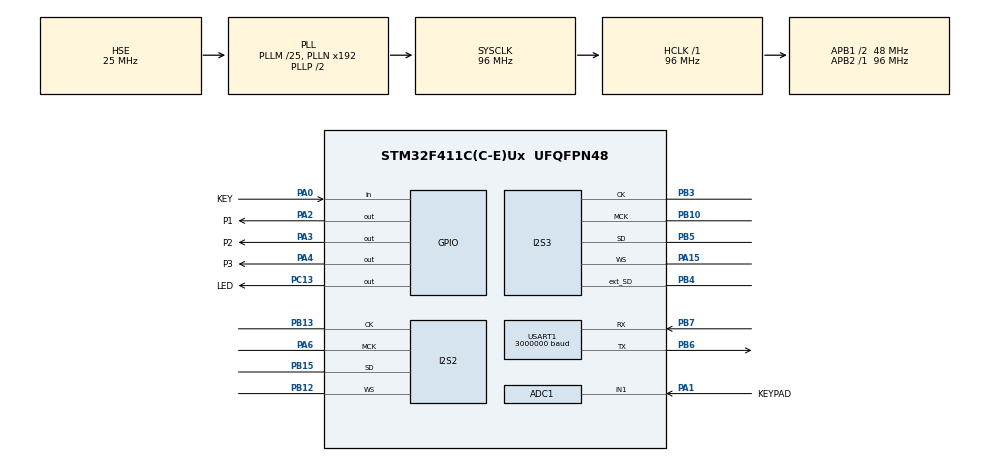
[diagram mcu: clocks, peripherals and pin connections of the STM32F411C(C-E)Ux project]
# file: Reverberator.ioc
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ADC1.Channel-0\#ChannelRegularConversion=ADC_CHANNEL_1
ADC1.ClockPrescaler=ADC_CLOCK_SYNC_PCLK_DIV8
ADC1.NbrOfConversionFlag=1
ADC1.Rank-0\#ChannelRegularConversion=1
ADC1.SamplingTime-0\#ChannelRegularConversion=ADC_SAMPLETIME_84CYCLES
ADC1.master=1
Dma.Request0=SPI3_RX
Dma.Request1=USART1_TX
Dma.Request2=SPI2_TX
Dma.SPI2_TX.2.Direction=DMA_MEMORY_TO_PERIPH
Dma.SPI2_TX.2.FIFOMode=DMA_FIFOMODE_DISABLE
Dma.SPI2_TX.2.Instance=DMA1_Stream4
Dma.SPI2_TX.2.MemDataAlignment=DMA_MDATAALIGN_HALFWORD
Dma.SPI2_TX.2.MemInc=DMA_MINC_ENABLE
Dma.SPI2_TX.2.Mode=DMA_CIRCULAR
Dma.SPI2_TX.2.PeriphDataAlignment=DMA_PDATAALIGN_HALFWORD
Dma.SPI2_TX.2.PeriphInc=DMA_PINC_DISABLE
Dma.SPI2_TX.2.Priority=DMA_PRIORITY_LOW
Dma.SPI3_RX.0.Direction=DMA_PERIPH_TO_MEMORY
Dma.SPI3_RX.0.FIFOMode=DMA_FIFOMODE_DISABLE
Dma.SPI3_RX.0.Instance=DMA1_Stream0
Dma.SPI3_RX.0.MemDataAlignment=DMA_MDATAALIGN_HALFWORD
Dma.SPI3_RX.0.MemInc=DMA_MINC_ENABLE
Dma.SPI3_RX.0.Mode=DMA_CIRCULAR
Dma.SPI3_RX.0.PeriphDataAlignment=DMA_PDATAALIGN_HALFWORD
Dma.SPI3_RX.0.PeriphInc=DMA_PINC_DISABLE
Dma.SPI3_RX.0.Priority=DMA_PRIORITY_LOW
Dma.USART1_TX.1.Direction=DMA_MEMORY_TO_PERIPH
Dma.USART1_TX.1.FIFOMode=DMA_FIFOMODE_DISABLE
Dma.USART1_TX.1.Instance=DMA2_Stream7
Dma.USART1_TX.1.MemDataAlignment=DMA_MDATAALIGN_BYTE
Dma.USART1_TX.1.MemInc=DMA_MINC_ENABLE
Dma.USART1_TX.1.Mode=DMA_NORMAL
Dma.USART1_TX.1.PeriphDataAlignment=DMA_PDATAALIGN_BYTE
Dma.USART1_TX.1.PeriphInc=DMA_PINC_DISABLE
Dma.USART1_TX.1.Priority=DMA_PRIORITY_LOW
FREERTOS.Queues01=keysQueue,16,uint8_t,0,Static,keysQueueBuffer,keysQueueControlBlock
FREERTOS.Tasks01=defaultTask,0,256,runDefaultTask,Default,NULL,Dynamic,NULL,NULL;keyboardTask,0,256,runKeyboardTask,Default,NULL,Dynamic,NULL,NULL
FREERTOS.configENABLE_FPU=1
FREERTOS.configUSE_NEWLIB_REENTRANT=1
I2S2.AudioFreq=I2S_AUDIOFREQ_48K
I2S2.DataFormat=I2S_DATAFORMAT_16B_EXTENDED
I2S2.ErrorAudioFreq=1.72 %
I2S2.FullDuplexMode=I2S_FULLDUPLEXMODE_DISABLE
I2S2.Instance=SPI$Index
I2S2.RealAudioFreq=48.828 KHz
I2S2.Standard=I2S_STANDARD_MSB
I2S2.VirtualMode=I2S_MODE_MASTER
I2S3.AudioFreq=I2S_AUDIOFREQ_48K
I2S3.DataFormat=I2S_DATAFORMAT_16B_EXTENDED
I2S3.ErrorAudioFreq=1.72 %
I2S3.FullDuplexMode=I2S_FULLDUPLEXMODE_ENABLE
I2S3.Instance=SPI$Index
I2S3.Mode=I2S_MODE_MASTER_RX
I2S3.RealAudioFreq=48.828 KHz
I2S3.Standard=I2S_STANDARD_PHILIPS
I2S3.VirtualMode=I2S_MODE_MASTER
Mcu.Family=STM32F4
Mcu.Name=STM32F411C(C-E)Ux
Mcu.Package=UFQFPN48
NVIC.DMA1_Stream0_IRQn=true\:5\:0\:false\:false\:true\:true\:false\:true
NVIC.DMA1_Stream4_IRQn=true\:5\:0\:false\:false\:true\:true\:false\:true
NVIC.DMA2_Stream7_IRQn=true\:5\:0\:false\:false\:true\:true\:false\:true
NVIC.PriorityGroup=NVIC_PRIORITYGROUP_4
NVIC.TIM1_UP_TIM10_IRQn=true\:15\:0\:false\:false\:true\:false\:false\:true
NVIC.TimeBase=TIM1_UP_TIM10_IRQn
NVIC.TimeBaseIP=TIM10
PA0-WKUP.GPIO_Label=KEY
PA0-WKUP.GPIO_PuPd=GPIO_PULLUP
PA0-WKUP.Signal=GPIO_Input
PA1.GPIO_Label=KEYPAD
PA1.Signal=ADCx_IN1
PA13.Mode=Serial_Wire
PA13.Signal=SYS_JTMS-SWDIO
PA14.Mode=Serial_Wire
PA14.Signal=SYS_JTCK-SWCLK
PA15.Mode=Full_Duplex_Master
PA15.Signal=I2S3_WS
PA2.GPIO_Label=P1
PA2.Signal=GPIO_Output
PA3.GPIO_Label=P2
PA3.Signal=GPIO_Output
PA4.GPIO_Label=P3
PA4.Signal=GPIO_Output
PA6.Mode=Master_Clock_Activated
PA6.Signal=I2S2_MCK
PB10.Mode=Master_Clock_Activated
PB10.Signal=I2S3_MCK
PB12.Mode=Half_Duplex_Master
PB12.Signal=I2S2_WS
PB13.Mode=Half_Duplex_Master
PB13.Signal=I2S2_CK
PB15.Mode=Half_Duplex_Master
PB15.Signal=I2S2_SD
PB3.Mode=Full_Duplex_Master
PB3.Signal=I2S3_CK
PB4.Mode=Full_Duplex_Master
PB4.Signal=I2S3_ext_SD
PB5.Mode=Full_Duplex_Master
PB5.Signal=I2S3_SD
PB6.Mode=Asynchronous
PB6.Signal=USART1_TX
PB7.Mode=Asynchronous
PB7.Signal=USART1_RX
PC13-ANTI_TAMP.GPIO_Label=LED
PC13-ANTI_TAMP.Signal=GPIO_Output
PC14-OSC32_IN.Mode=LSE-External-Oscillator
PC14-OSC32_IN.Signal=RCC_OSC32_IN
PC15-OSC32_OUT.Mode=LSE-External-Oscillator
PC15-OSC32_OUT.Signal=RCC_OSC32_OUT
PH0\ -\ OSC_IN.Mode=HSE-External-Oscillator
PH0\ -\ OSC_IN.Signal=RCC_OSC_IN
PH1\ -\ OSC_OUT.Mode=HSE-External-Oscillator
PH1\ -\ OSC_OUT.Signal=RCC_OSC_OUT
ProjectManager.HeapSize=0x8000
ProjectManager.StackSize=0x400
ProjectManager.TargetToolchain=STM32CubeIDE
RCC.48MHZClocksFreq_Value=48000000
RCC.AHBFreq_Value=96000000
RCC.APB1CLKDivider=RCC_HCLK_DIV2
RCC.APB1Freq_Value=48000000
RCC.APB1TimFreq_Value=96000000
RCC.APB2Freq_Value=96000000
RCC.APB2TimFreq_Value=96000000
RCC.CortexFreq_Value=96000000
RCC.HCLKFreq_Value=96000000
RCC.HSE_VALUE=25000000
RCC.HSI_VALUE=16000000
RCC.PLLM=25
RCC.PLLSourceVirtual=RCC_PLLSOURCE_HSE
RCC.SYSCLKFreq_VALUE=96000000
RCC.SYSCLKSource=RCC_SYSCLKSOURCE_PLLCLK
RCC.VCOOutputFreq_Value=192000000
SH.ADCx_IN1.0=ADC1_IN1,IN1
USART1.BaudRate=3000000
USART1.VirtualMode=VM_ASYNC
VP_FREERTOS_VS_CMSIS_V1.Mode=CMSIS_V1
VP_SYS_VS_tim10.Mode=TIM10
board=custom

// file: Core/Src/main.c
/* USER CODE BEGIN Header */
/**
  ******************************************************************************
  * @file           : main.c
  * @brief          : Main program body
  ******************************************************************************
  * @attention
  *
  * Copyright (c) 2022 STMicroelectronics.
  * All rights reserved.
  *
  * This software is licensed under terms that can be found in the LICENSE file
  * in the root directory of this software component.
  * If no LICENSE file comes with this software, it is provided AS-IS.
  *
  ******************************************************************************
  */
/* USER CODE END Header */
#include "main.h"
#include "cmsis_os.h"

/* USER CODE BEGIN Includes */
#include "processing.h"
#include "interface.h"

/* USER CODE END Includes */

ADC_HandleTypeDef hadc1;

I2S_HandleTypeDef hi2s2;
I2S_HandleTypeDef hi2s3;
DMA_HandleTypeDef hdma_spi2_tx;
DMA_HandleTypeDef hdma_spi3_rx;

UART_HandleTypeDef huart1;
DMA_HandleTypeDef hdma_usart1_tx;

osThreadId defaultTaskHandle;
osThreadId keyboardTaskHandle;
osMessageQId keysQueueHandle;
uint8_t keysQueueBuffer[ 16 * sizeof( uint8_t ) ];
osStaticMessageQDef_t keysQueueControlBlock;

void SystemClock_Config(void);
void PeriphCommonClock_Config(void);
static void MX_GPIO_Init(void);
static void MX_DMA_Init(void);
static void MX_I2S3_Init(void);
static void MX_USART1_UART_Init(void);
static void MX_I2S2_Init(void);
static void MX_ADC1_Init(void);
void runDefaultTask(void const * argument);
void runKeyboardTask(void const * argument);

int main(void)
{

  /* MCU Configuration--------------------------------------------------------*/

  /* Reset of all peripherals, Initializes the Flash interface and the Systick. */
  HAL_Init();

  /* Configure the system clock */
  SystemClock_Config();

/* Configure the peripherals common clocks */
  PeriphCommonClock_Config();

  /* Initialize all configured peripherals */
  MX_GPIO_Init();
  MX_DMA_Init();
  MX_I2S3_Init();
  MX_USART1_UART_Init();
  MX_I2S2_Init();
  MX_ADC1_Init();

  /* Create the queue(s) */
  /* definition and creation of keysQueue */
  osMessageQStaticDef(keysQueue, 16, uint8_t, keysQueueBuffer, &keysQueueControlBlock);
  keysQueueHandle = osMessageCreate(osMessageQ(keysQueue), NULL);

  /* Create the thread(s) */
  /* definition and creation of defaultTask */
  osThreadDef(defaultTask, runDefaultTask, osPriorityNormal, 0, 256);
  defaultTaskHandle = osThreadCreate(osThread(defaultTask), NULL);

  /* definition and creation of keyboardTask */
  osThreadDef(keyboardTask, runKeyboardTask, osPriorityNormal, 0, 256);
  keyboardTaskHandle = osThreadCreate(osThread(keyboardTask), NULL);

  /* Start scheduler */
  osKernelStart();

  /* We should never get here as control is now taken by the scheduler */
  /* Infinite loop */
  while (1)
  {

  }
}

void SystemClock_Config(void)
{
  RCC_OscInitTypeDef RCC_OscInitStruct = {0};
  RCC_ClkInitTypeDef RCC_ClkInitStruct = {0};

  /** Configure the main internal regulator output voltage
  */
  __HAL_RCC_PWR_CLK_ENABLE();
  __HAL_PWR_VOLTAGESCALING_CONFIG(PWR_REGULATOR_VOLTAGE_SCALE1);
  /** Initializes the RCC Oscillators according to the specified parameters
  * in the RCC_OscInitTypeDef structure.
  */
  RCC_OscInitStruct.OscillatorType = RCC_OSCILLATORTYPE_HSE;
  RCC_OscInitStruct.HSEState = RCC_HSE_ON;
  RCC_OscInitStruct.PLL.PLLState = RCC_PLL_ON;
  RCC_OscInitStruct.PLL.PLLSource = RCC_PLLSOURCE_HSE;
  RCC_OscInitStruct.PLL.PLLM = 25;
  RCC_OscInitStruct.PLL.PLLN = 192;
  RCC_OscInitStruct.PLL.PLLP = RCC_PLLP_DIV2;
  RCC_OscInitStruct.PLL.PLLQ = 4;
  if (HAL_RCC_OscConfig(&RCC_OscInitStruct) != HAL_OK)
  {
    Error_Handler();
  }
  /** Initializes the CPU, AHB and APB buses clocks
  */
  RCC_ClkInitStruct.ClockType = RCC_CLOCKTYPE_HCLK|RCC_CLOCKTYPE_SYSCLK
                              |RCC_CLOCKTYPE_PCLK1|RCC_CLOCKTYPE_PCLK2;
  RCC_ClkInitStruct.SYSCLKSource = RCC_SYSCLKSOURCE_PLLCLK;
  RCC_ClkInitStruct.AHBCLKDivider = RCC_SYSCLK_DIV1;
  RCC_ClkInitStruct.APB1CLKDivider = RCC_HCLK_DIV2;
  RCC_ClkInitStruct.APB2CLKDivider = RCC_HCLK_DIV1;

  if (HAL_RCC_ClockConfig(&RCC_ClkInitStruct, FLASH_LATENCY_3) != HAL_OK)
  {
    Error_Handler();
  }
}

void PeriphCommonClock_Config(void)
{
  RCC_PeriphCLKInitTypeDef PeriphClkInitStruct = {0};

  /** Initializes the peripherals clock
  */
  PeriphClkInitStruct.PeriphClockSelection = RCC_PERIPHCLK_I2S;
  PeriphClkInitStruct.PLLI2S.PLLI2SN = 192;
  PeriphClkInitStruct.PLLI2S.PLLI2SM = 16;
  PeriphClkInitStruct.PLLI2S.PLLI2SR = 2;
  if (HAL_RCCEx_PeriphCLKConfig(&PeriphClkInitStruct) != HAL_OK)
  {
    Error_Handler();
  }
}

static void MX_ADC1_Init(void)
{

  ADC_ChannelConfTypeDef sConfig = {0};

  /** Configure the global features of the ADC (Clock, Resolution, Data Alignment and number of conversion)
  */
  hadc1.Instance = ADC1;
  hadc1.Init.ClockPrescaler = ADC_CLOCK_SYNC_PCLK_DIV8;
  hadc1.Init.Resolution = ADC_RESOLUTION_12B;
  hadc1.Init.ScanConvMode = DISABLE;
  hadc1.Init.ContinuousConvMode = DISABLE;
  hadc1.Init.DiscontinuousConvMode = DISABLE;
  hadc1.Init.ExternalTrigConvEdge = ADC_EXTERNALTRIGCONVEDGE_NONE;
  hadc1.Init.ExternalTrigConv = ADC_SOFTWARE_START;
  hadc1.Init.DataAlign = ADC_DATAALIGN_RIGHT;
  hadc1.Init.NbrOfConversion = 1;
  hadc1.Init.DMAContinuousRequests = DISABLE;
  hadc1.Init.EOCSelection = ADC_EOC_SINGLE_CONV;
  if (HAL_ADC_Init(&hadc1) != HAL_OK)
  {
    Error_Handler();
  }
  /** Configure for the selected ADC regular channel its corresponding rank in the sequencer and its sample time.
  */
  sConfig.Channel = ADC_CHANNEL_1;
  sConfig.Rank = 1;
  sConfig.SamplingTime = ADC_SAMPLETIME_84CYCLES;
  if (HAL_ADC_ConfigChannel(&hadc1, &sConfig) != HAL_OK)
  {
    Error_Handler();
  }

}

static void MX_I2S2_Init(void)
{

  hi2s2.Instance = SPI2;
  hi2s2.Init.Mode = I2S_MODE_MASTER_TX;
  hi2s2.Init.Standard = I2S_STANDARD_MSB;
  hi2s2.Init.DataFormat = I2S_DATAFORMAT_16B_EXTENDED;
  hi2s2.Init.MCLKOutput = I2S_MCLKOUTPUT_ENABLE;
  hi2s2.Init.AudioFreq = I2S_AUDIOFREQ_48K;
  hi2s2.Init.CPOL = I2S_CPOL_LOW;
  hi2s2.Init.ClockSource = I2S_CLOCK_PLL;
  hi2s2.Init.FullDuplexMode = I2S_FULLDUPLEXMODE_DISABLE;
  if (HAL_I2S_Init(&hi2s2) != HAL_OK)
  {
    Error_Handler();
  }

}

static void MX_I2S3_Init(void)
{

  hi2s3.Instance = SPI3;
  hi2s3.Init.Mode = I2S_MODE_MASTER_RX;
  hi2s3.Init.Standard = I2S_STANDARD_PHILIPS;
  hi2s3.Init.DataFormat = I2S_DATAFORMAT_16B_EXTENDED;
  hi2s3.Init.MCLKOutput = I2S_MCLKOUTPUT_ENABLE;
  hi2s3.Init.AudioFreq = I2S_AUDIOFREQ_48K;
  hi2s3.Init.CPOL = I2S_CPOL_LOW;
  hi2s3.Init.ClockSource = I2S_CLOCK_PLL;
  hi2s3.Init.FullDuplexMode = I2S_FULLDUPLEXMODE_ENABLE;
  if (HAL_I2S_Init(&hi2s3) != HAL_OK)
  {
    Error_Handler();
  }

}

static void MX_USART1_UART_Init(void)
{

  huart1.Instance = USART1;
  huart1.Init.BaudRate = 3000000;
  huart1.Init.WordLength = UART_WORDLENGTH_8B;
  huart1.Init.StopBits = UART_STOPBITS_1;
  huart1.Init.Parity = UART_PARITY_NONE;
  huart1.Init.Mode = UART_MODE_TX_RX;
  huart1.Init.HwFlowCtl = UART_HWCONTROL_NONE;
  huart1.Init.OverSampling = UART_OVERSAMPLING_16;
  if (HAL_UART_Init(&huart1) != HAL_OK)
  {
    Error_Handler();
  }

}

static void MX_DMA_Init(void)
{

  /* DMA controller clock enable */
  __HAL_RCC_DMA1_CLK_ENABLE();
  __HAL_RCC_DMA2_CLK_ENABLE();

  /* DMA interrupt init */
  /* DMA1_Stream0_IRQn interrupt configuration */
  HAL_NVIC_SetPriority(DMA1_Stream0_IRQn, 5, 0);
  HAL_NVIC_EnableIRQ(DMA1_Stream0_IRQn);
  /* DMA1_Stream4_IRQn interrupt configuration */
  HAL_NVIC_SetPriority(DMA1_Stream4_IRQn, 5, 0);
  HAL_NVIC_EnableIRQ(DMA1_Stream4_IRQn);
  /* DMA2_Stream7_IRQn interrupt configuration */
  HAL_NVIC_SetPriority(DMA2_Stream7_IRQn, 5, 0);
  HAL_NVIC_EnableIRQ(DMA2_Stream7_IRQn);

}

static void MX_GPIO_Init(void)
{
  GPIO_InitTypeDef GPIO_InitStruct = {0};

  /* GPIO Ports Clock Enable */
  __HAL_RCC_GPIOC_CLK_ENABLE();
  __HAL_RCC_GPIOH_CLK_ENABLE();
  __HAL_RCC_GPIOA_CLK_ENABLE();
  __HAL_RCC_GPIOB_CLK_ENABLE();

  /*Configure GPIO pin Output Level */
  HAL_GPIO_WritePin(LED_GPIO_Port, LED_Pin, GPIO_PIN_RESET);

  /*Configure GPIO pin Output Level */
  HAL_GPIO_WritePin(GPIOA, P1_Pin|P2_Pin|P3_Pin, GPIO_PIN_RESET);

  /*Configure GPIO pin : LED_Pin */
  GPIO_InitStruct.Pin = LED_Pin;
  GPIO_InitStruct.Mode = GPIO_MODE_OUTPUT_PP;
  GPIO_InitStruct.Pull = GPIO_NOPULL;
  GPIO_InitStruct.Speed = GPIO_SPEED_FREQ_LOW;
  HAL_GPIO_Init(LED_GPIO_Port, &GPIO_InitStruct);

  /*Configure GPIO pin : KEY_Pin */
  GPIO_InitStruct.Pin = KEY_Pin;
  GPIO_InitStruct.Mode = GPIO_MODE_INPUT;
  GPIO_InitStruct.Pull = GPIO_PULLUP;
  HAL_GPIO_Init(KEY_GPIO_Port, &GPIO_InitStruct);

  /*Configure GPIO pins : P1_Pin P2_Pin P3_Pin */
  GPIO_InitStruct.Pin = P1_Pin|P2_Pin|P3_Pin;
  GPIO_InitStruct.Mode = GPIO_MODE_OUTPUT_PP;
  GPIO_InitStruct.Pull = GPIO_NOPULL;
  GPIO_InitStruct.Speed = GPIO_SPEED_FREQ_LOW;
  HAL_GPIO_Init(GPIOA, &GPIO_InitStruct);

}

void runDefaultTask(void const * argument)
{
  /* USER CODE BEGIN 5 */
  /* Infinite loop */
  Interface_DefaultTask();
  /* USER CODE END 5 */
}

void runKeyboardTask(void const * argument)
{
  /* USER CODE BEGIN runKeyboardTask */
  /* Infinite loop */
  Interface_KeyboardTask();
  /* USER CODE END runKeyboardTask */
}

void HAL_TIM_PeriodElapsedCallback(TIM_HandleTypeDef *htim)
{
  if (htim->Instance == TIM10) {
    HAL_IncTick();
  }
}

void Error_Handler(void)
{
  __disable_irq();
  while (1)
  {
  }
}
